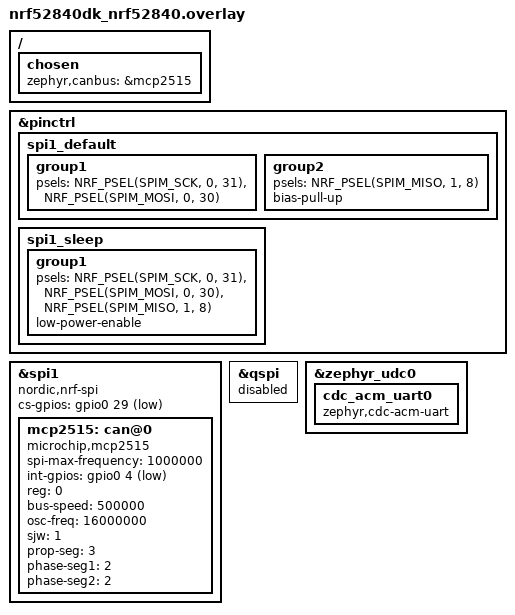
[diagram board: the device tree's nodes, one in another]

/ {
	chosen {
		zephyr,canbus = &mcp2515;
	};
};

&pinctrl {
	spi1_default: spi1_default {
		group1 {
			psels = <NRF_PSEL(SPIM_SCK, 0, 31)>,
				<NRF_PSEL(SPIM_MOSI, 0, 30)>;
		};
		group2 {
			psels = <NRF_PSEL(SPIM_MISO, 1, 8)>;
			bias-pull-up;
		};
	};

	spi1_sleep: spi1_sleep {
		group1 {
			psels = <NRF_PSEL(SPIM_SCK, 0, 31)>,
			        <NRF_PSEL(SPIM_MOSI, 0, 30)>,
			        <NRF_PSEL(SPIM_MISO, 1, 8)>;
			low-power-enable;
		};
	};
};

&spi1 {
	compatible = "nordic,nrf-spi";
	status = "okay";
	cs-gpios = <&gpio0 29  (GPIO_ACTIVE_LOW | GPIO_PULL_UP)>;

	mcp2515: can@0 {
		compatible = "microchip,mcp2515";
		spi-max-frequency = <1000000>;
		int-gpios = <&gpio0 4 (GPIO_ACTIVE_LOW | GPIO_PULL_UP)>;
		status = "okay";
		reg = <0>;
		#address-cells = <1>;
		#size-cells = <0>;
		bus-speed = <500000>;
		osc-freq = <16000000>;
		sjw = <1>;
		prop-seg = <3>;
		phase-seg1 = <2>;
		phase-seg2 = <2>;
	};
};

&qspi {
	status = "disabled";
};

&zephyr_udc0 {
	cdc_acm_uart0: cdc_acm_uart0 {
		compatible = "zephyr,cdc-acm-uart";
	};
};
